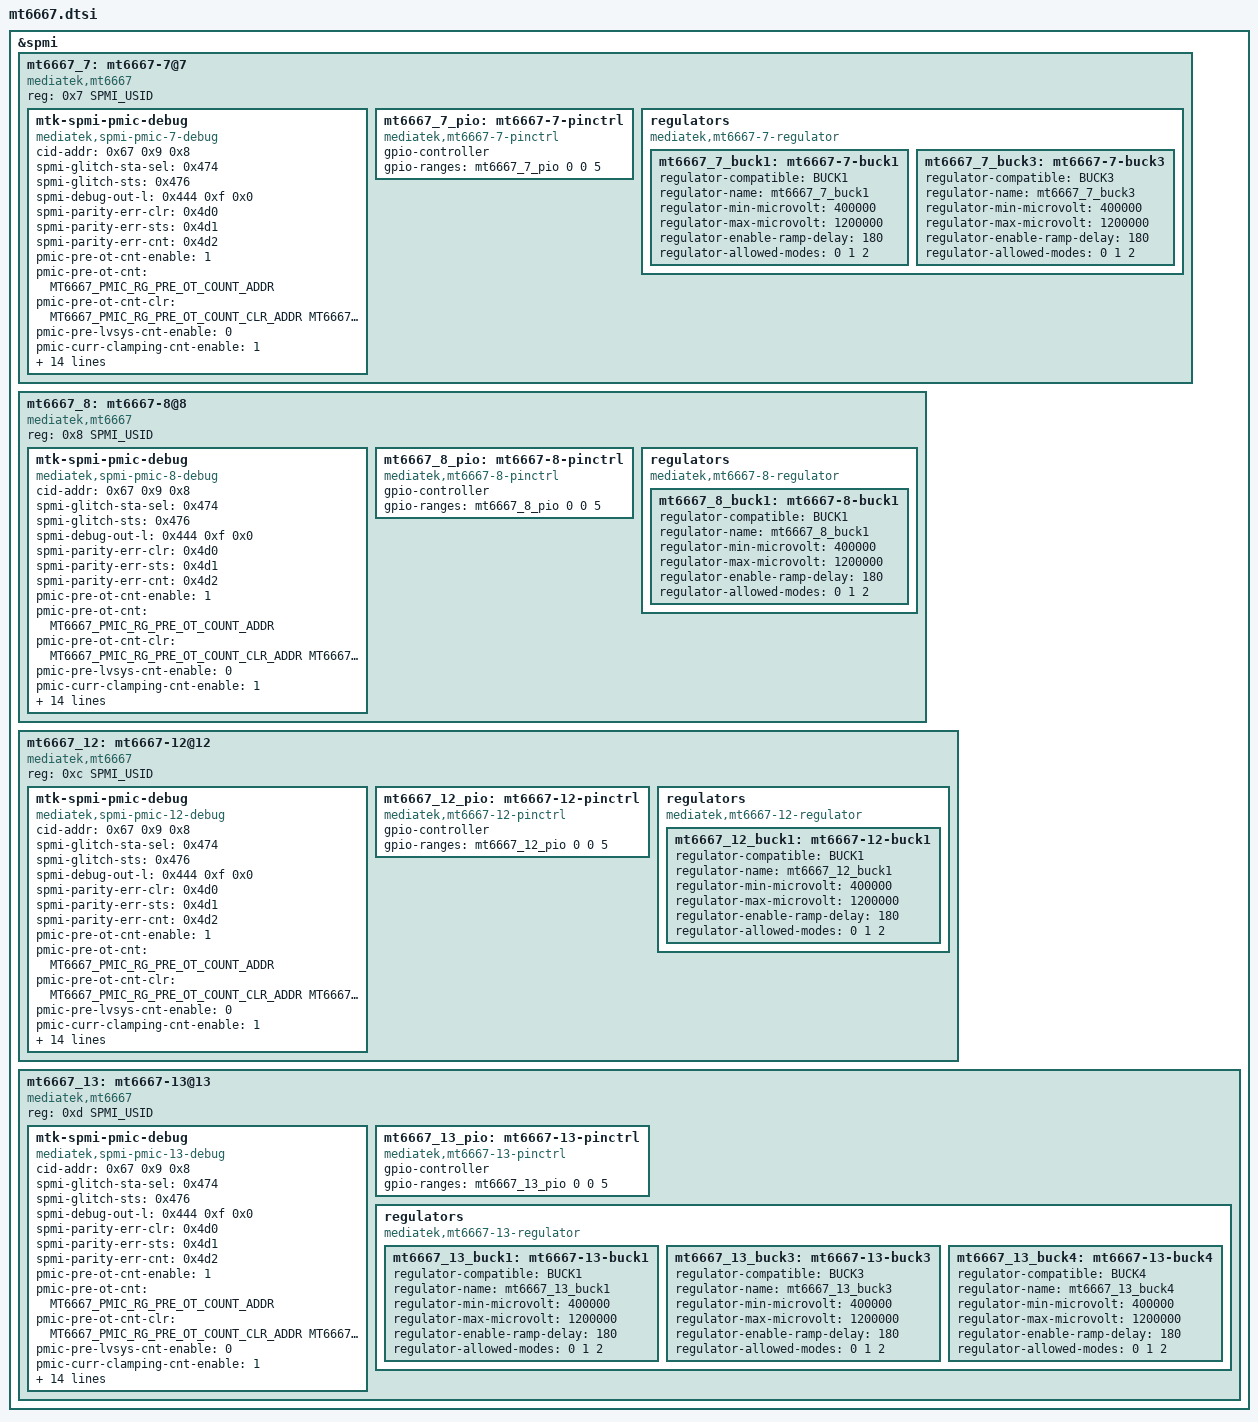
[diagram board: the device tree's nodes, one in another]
// SPDX-License-Identifier: GPL-2.0
/*
 * Copyright (c) 2024 MediaTek Inc.
 */
#include <dt-bindings/iio/mt635x-auxadc.h>
#include <dt-bindings/spmi/spmi.h>
#include <linux/mfd/mt6667/registers.h>

&spmi {
	#address-cells = <2>;
	#size-cells = <0>;
	mt6667_7: mt6667-7@7 {
		compatible = "mediatek,mt6667";
		reg = <0x7 SPMI_USID>;

		mtk-spmi-pmic-debug {
			compatible = "mediatek,spmi-pmic-7-debug";
			cid-addr = <0x67 0x9 0x8>;
			spmi-glitch-sta-sel = <0x474>;
			spmi-glitch-sts = <0x476>;
			spmi-debug-out-l = <0x444 0xf 0x0>;
			spmi-parity-err-clr = <0x4d0>;
			spmi-parity-err-sts = <0x4d1>;
			spmi-parity-err-cnt = <0x4d2>;
			pmic-pre-ot-cnt-enable = <1>;
			pmic-pre-ot-cnt = <MT6667_PMIC_RG_PRE_OT_COUNT_ADDR>;
			pmic-pre-ot-cnt-clr = <MT6667_PMIC_RG_PRE_OT_COUNT_CLR_ADDR
					       MT6667_PMIC_RG_PRE_OT_COUNT_CLR_MASK
					       MT6667_PMIC_RG_PRE_OT_COUNT_CLR_SHIFT>;
			pmic-pre-lvsys-cnt-enable = <0>;
			pmic-curr-clamping-cnt-enable = <1>;
			pmic-curr-clamping-cnt = <MT6667_PMIC_RG_BUCK1_OC_STS_CNT_ADDR
						  MT6667_PMIC_RG_BUCK2_OC_STS_CNT_ADDR
						  MT6667_PMIC_RG_BUCK3_OC_STS_CNT_ADDR
						  MT6667_PMIC_RG_BUCK4_OC_STS_CNT_ADDR>;
			pmic-curr-clamping-cnt-clr = <MT6667_PMIC_RG_BUCK_OC_STS_CNT_CLR_ADDR
						      MT6667_PMIC_RG_BUCK_OC_STS_CNT_CLR_MASK
						      MT6667_PMIC_RG_BUCK_OC_STS_CNT_CLR_SHIFT>;
			spmi-pmic-debug-rg-enable = <1>;
			spmi-pmic-debug-rg-addr = <MT6667_RG_SMT_SPMI_M_SCL_ADDR
						   MT6667_RG_SMT_SPMI_M_SDA_ADDR
						   MT6667_RG_OCTL_SPMI_M_SDA_ADDR
						   MT6667_GPIO_PULLEN0_4_ADDR
						   MT6667_GPIO_PULLEN0_5_ADDR
						   MT6667_RG_TOP_CFG_RSV1_0_ADDR
						   MT6667_RG_TOP_CFG_RSV1_1_ADDR
						   MT6667_GPIO_PULLSEL0_4_ADDR
						   MT6667_GPIO_PULLSEL0_5_ADDR>;
			spmi-pmic-debug-rg-mask = <MT6667_RG_SMT_SPMI_M_SCL_MASK
						   MT6667_RG_SMT_SPMI_M_SDA_MASK
						   MT6667_RG_OCTL_SPMI_M_SDA_MASK
						   MT6667_GPIO_PULLEN0_4_MASK
						   MT6667_GPIO_PULLEN0_5_MASK
						   MT6667_RG_TOP_CFG_RSV1_0_MASK
						   MT6667_RG_TOP_CFG_RSV1_1_MASK
						   MT6667_GPIO_PULLSEL0_4_MASK
						   MT6667_GPIO_PULLSEL0_5_MASK>;
			spmi-pmic-debug-rg-shift = <MT6667_RG_SMT_SPMI_M_SCL_SHIFT
						    MT6667_RG_SMT_SPMI_M_SDA_SHIFT
						    MT6667_RG_OCTL_SPMI_M_SDA_SHIFT
						    MT6667_GPIO_PULLEN0_4_SHIFT
						    MT6667_GPIO_PULLEN0_5_SHIFT
						    MT6667_RG_TOP_CFG_RSV1_0_SHIFT
						    MT6667_RG_TOP_CFG_RSV1_1_SHIFT
						    MT6667_GPIO_PULLSEL0_4_SHIFT
						    MT6667_GPIO_PULLSEL0_5_SHIFT>;
			rgs-npkt-cclp-err = <MT6667_RGS_NPKT_CCLP_ERR>;
			rgs-npkt-cclp-clr = <MT6667_RGS_NPKT_CCLP_CLR>;
			rgs-npkt-cclp-clr-enable = <1>;
		};

		mt6667_7_pio: mt6667-7-pinctrl {
			compatible = "mediatek,mt6667-7-pinctrl";
			gpio-controller;
			#gpio-cells = <2>;
			gpio-ranges = <&mt6667_7_pio 0 0 5>;
		};

		regulators {
			compatible = "mediatek,mt6667-7-regulator";
			mt6667_7_buck1: mt6667-7-buck1 {
				regulator-compatible = "BUCK1";
				regulator-name = "mt6667_7_buck1";
				regulator-min-microvolt = <400000>;
				regulator-max-microvolt = <1200000>;
				regulator-enable-ramp-delay = <180>;
				regulator-allowed-modes = <0 1 2>;
			};
			mt6667_7_buck3: mt6667-7-buck3 {
				regulator-compatible = "BUCK3";
				regulator-name = "mt6667_7_buck3";
				regulator-min-microvolt = <400000>;
				regulator-max-microvolt = <1200000>;
				regulator-enable-ramp-delay = <180>;
				regulator-allowed-modes = <0 1 2>;
				// regulator-always-on; // MM TODO:
			};
		};
	};

	mt6667_8: mt6667-8@8 {
		compatible = "mediatek,mt6667";
		reg = <0x8 SPMI_USID>;

		mtk-spmi-pmic-debug {
			compatible = "mediatek,spmi-pmic-8-debug";
			cid-addr = <0x67 0x9 0x8>;
			spmi-glitch-sta-sel = <0x474>;
			spmi-glitch-sts = <0x476>;
			spmi-debug-out-l = <0x444 0xf 0x0>;
			spmi-parity-err-clr = <0x4d0>;
			spmi-parity-err-sts = <0x4d1>;
			spmi-parity-err-cnt = <0x4d2>;
			pmic-pre-ot-cnt-enable = <1>;
			pmic-pre-ot-cnt = <MT6667_PMIC_RG_PRE_OT_COUNT_ADDR>;
			pmic-pre-ot-cnt-clr = <MT6667_PMIC_RG_PRE_OT_COUNT_CLR_ADDR
					       MT6667_PMIC_RG_PRE_OT_COUNT_CLR_MASK
					       MT6667_PMIC_RG_PRE_OT_COUNT_CLR_SHIFT>;
			pmic-pre-lvsys-cnt-enable = <0>;
			pmic-curr-clamping-cnt-enable = <1>;
			pmic-curr-clamping-cnt = <MT6667_PMIC_RG_BUCK1_OC_STS_CNT_ADDR
						  MT6667_PMIC_RG_BUCK2_OC_STS_CNT_ADDR
						  MT6667_PMIC_RG_BUCK3_OC_STS_CNT_ADDR
						  MT6667_PMIC_RG_BUCK4_OC_STS_CNT_ADDR>;
			pmic-curr-clamping-cnt-clr = <MT6667_PMIC_RG_BUCK_OC_STS_CNT_CLR_ADDR
						      MT6667_PMIC_RG_BUCK_OC_STS_CNT_CLR_MASK
						      MT6667_PMIC_RG_BUCK_OC_STS_CNT_CLR_SHIFT>;
			spmi-pmic-debug-rg-enable = <1>;
			spmi-pmic-debug-rg-addr = <MT6667_RG_SMT_SPMI_M_SCL_ADDR
						   MT6667_RG_SMT_SPMI_M_SDA_ADDR
						   MT6667_RG_OCTL_SPMI_M_SDA_ADDR
						   MT6667_GPIO_PULLEN0_4_ADDR
						   MT6667_GPIO_PULLEN0_5_ADDR
						   MT6667_RG_TOP_CFG_RSV1_0_ADDR
						   MT6667_RG_TOP_CFG_RSV1_1_ADDR
						   MT6667_GPIO_PULLSEL0_4_ADDR
						   MT6667_GPIO_PULLSEL0_5_ADDR>;
			spmi-pmic-debug-rg-mask = <MT6667_RG_SMT_SPMI_M_SCL_MASK
						   MT6667_RG_SMT_SPMI_M_SDA_MASK
						   MT6667_RG_OCTL_SPMI_M_SDA_MASK
						   MT6667_GPIO_PULLEN0_4_MASK
						   MT6667_GPIO_PULLEN0_5_MASK
						   MT6667_RG_TOP_CFG_RSV1_0_MASK
						   MT6667_RG_TOP_CFG_RSV1_1_MASK
						   MT6667_GPIO_PULLSEL0_4_MASK
						   MT6667_GPIO_PULLSEL0_5_MASK>;
			spmi-pmic-debug-rg-shift = <MT6667_RG_SMT_SPMI_M_SCL_SHIFT
						    MT6667_RG_SMT_SPMI_M_SDA_SHIFT
						    MT6667_RG_OCTL_SPMI_M_SDA_SHIFT
						    MT6667_GPIO_PULLEN0_4_SHIFT
						    MT6667_GPIO_PULLEN0_5_SHIFT
						    MT6667_RG_TOP_CFG_RSV1_0_SHIFT
						    MT6667_RG_TOP_CFG_RSV1_1_SHIFT
						    MT6667_GPIO_PULLSEL0_4_SHIFT
						    MT6667_GPIO_PULLSEL0_5_SHIFT>;
			rgs-npkt-cclp-err = <MT6667_RGS_NPKT_CCLP_ERR>;
			rgs-npkt-cclp-clr = <MT6667_RGS_NPKT_CCLP_CLR>;
			rgs-npkt-cclp-clr-enable = <1>;
		};

		mt6667_8_pio: mt6667-8-pinctrl {
			compatible = "mediatek,mt6667-8-pinctrl";
			gpio-controller;
			#gpio-cells = <2>;
			gpio-ranges = <&mt6667_8_pio 0 0 5>;
		};

		regulators {
			compatible = "mediatek,mt6667-8-regulator";
			mt6667_8_buck1: mt6667-8-buck1 {
				regulator-compatible = "BUCK1";
				regulator-name = "mt6667_8_buck1";
				regulator-min-microvolt = <400000>;
				regulator-max-microvolt = <1200000>;
				regulator-enable-ramp-delay = <180>;
				regulator-allowed-modes = <0 1 2>;
			};
		};
	};

	mt6667_12: mt6667-12@12 {
		compatible = "mediatek,mt6667";
		reg = <0xc SPMI_USID>;

		mtk-spmi-pmic-debug {
			compatible = "mediatek,spmi-pmic-12-debug";
			cid-addr = <0x67 0x9 0x8>;
			spmi-glitch-sta-sel = <0x474>;
			spmi-glitch-sts = <0x476>;
			spmi-debug-out-l = <0x444 0xf 0x0>;
			spmi-parity-err-clr = <0x4d0>;
			spmi-parity-err-sts = <0x4d1>;
			spmi-parity-err-cnt = <0x4d2>;
			pmic-pre-ot-cnt-enable = <1>;
			pmic-pre-ot-cnt = <MT6667_PMIC_RG_PRE_OT_COUNT_ADDR>;
			pmic-pre-ot-cnt-clr = <MT6667_PMIC_RG_PRE_OT_COUNT_CLR_ADDR
					       MT6667_PMIC_RG_PRE_OT_COUNT_CLR_MASK
					       MT6667_PMIC_RG_PRE_OT_COUNT_CLR_SHIFT>;
			pmic-pre-lvsys-cnt-enable = <0>;
			pmic-curr-clamping-cnt-enable = <1>;
			pmic-curr-clamping-cnt = <MT6667_PMIC_RG_BUCK1_OC_STS_CNT_ADDR
						  MT6667_PMIC_RG_BUCK2_OC_STS_CNT_ADDR
						  MT6667_PMIC_RG_BUCK3_OC_STS_CNT_ADDR
						  MT6667_PMIC_RG_BUCK4_OC_STS_CNT_ADDR>;
			pmic-curr-clamping-cnt-clr = <MT6667_PMIC_RG_BUCK_OC_STS_CNT_CLR_ADDR
						      MT6667_PMIC_RG_BUCK_OC_STS_CNT_CLR_MASK
						      MT6667_PMIC_RG_BUCK_OC_STS_CNT_CLR_SHIFT>;
			spmi-pmic-debug-rg-enable = <1>;
			spmi-pmic-debug-rg-addr = <MT6667_RG_SMT_SPMI_M_SCL_ADDR
						   MT6667_RG_SMT_SPMI_M_SDA_ADDR
						   MT6667_RG_OCTL_SPMI_M_SDA_ADDR
						   MT6667_GPIO_PULLEN0_4_ADDR
						   MT6667_GPIO_PULLEN0_5_ADDR
						   MT6667_RG_TOP_CFG_RSV1_0_ADDR
						   MT6667_RG_TOP_CFG_RSV1_1_ADDR
						   MT6667_GPIO_PULLSEL0_4_ADDR
						   MT6667_GPIO_PULLSEL0_5_ADDR>;
			spmi-pmic-debug-rg-mask = <MT6667_RG_SMT_SPMI_M_SCL_MASK
						   MT6667_RG_SMT_SPMI_M_SDA_MASK
						   MT6667_RG_OCTL_SPMI_M_SDA_MASK
						   MT6667_GPIO_PULLEN0_4_MASK
						   MT6667_GPIO_PULLEN0_5_MASK
						   MT6667_RG_TOP_CFG_RSV1_0_MASK
						   MT6667_RG_TOP_CFG_RSV1_1_MASK
						   MT6667_GPIO_PULLSEL0_4_MASK
						   MT6667_GPIO_PULLSEL0_5_MASK>;
			spmi-pmic-debug-rg-shift = <MT6667_RG_SMT_SPMI_M_SCL_SHIFT
						    MT6667_RG_SMT_SPMI_M_SDA_SHIFT
						    MT6667_RG_OCTL_SPMI_M_SDA_SHIFT
						    MT6667_GPIO_PULLEN0_4_SHIFT
						    MT6667_GPIO_PULLEN0_5_SHIFT
						    MT6667_RG_TOP_CFG_RSV1_0_SHIFT
						    MT6667_RG_TOP_CFG_RSV1_1_SHIFT
						    MT6667_GPIO_PULLSEL0_4_SHIFT
						    MT6667_GPIO_PULLSEL0_5_SHIFT>;
			rgs-npkt-cclp-err = <MT6667_RGS_NPKT_CCLP_ERR>;
			rgs-npkt-cclp-clr = <MT6667_RGS_NPKT_CCLP_CLR>;
			rgs-npkt-cclp-clr-enable = <1>;
		};

		mt6667_12_pio: mt6667-12-pinctrl {
			compatible = "mediatek,mt6667-12-pinctrl";
			gpio-controller;
			#gpio-cells = <2>;
			gpio-ranges = <&mt6667_12_pio 0 0 5>;
		};

		regulators {
			compatible = "mediatek,mt6667-12-regulator";
			mt6667_12_buck1: mt6667-12-buck1 {
				regulator-compatible = "BUCK1";
				regulator-name = "mt6667_12_buck1";
				regulator-min-microvolt = <400000>;
				regulator-max-microvolt = <1200000>;
				regulator-enable-ramp-delay = <180>;
				regulator-allowed-modes = <0 1 2>;
			};
		};
	};

	mt6667_13: mt6667-13@13 {
		compatible = "mediatek,mt6667";
		reg = <0xd SPMI_USID>;

		mtk-spmi-pmic-debug {
			compatible = "mediatek,spmi-pmic-13-debug";
			cid-addr = <0x67 0x9 0x8>;
			spmi-glitch-sta-sel = <0x474>;
			spmi-glitch-sts = <0x476>;
			spmi-debug-out-l = <0x444 0xf 0x0>;
			spmi-parity-err-clr = <0x4d0>;
			spmi-parity-err-sts = <0x4d1>;
			spmi-parity-err-cnt = <0x4d2>;
			pmic-pre-ot-cnt-enable = <1>;
			pmic-pre-ot-cnt = <MT6667_PMIC_RG_PRE_OT_COUNT_ADDR>;
			pmic-pre-ot-cnt-clr = <MT6667_PMIC_RG_PRE_OT_COUNT_CLR_ADDR
					       MT6667_PMIC_RG_PRE_OT_COUNT_CLR_MASK
					       MT6667_PMIC_RG_PRE_OT_COUNT_CLR_SHIFT>;
			pmic-pre-lvsys-cnt-enable = <0>;
			pmic-curr-clamping-cnt-enable = <1>;
			pmic-curr-clamping-cnt = <MT6667_PMIC_RG_BUCK1_OC_STS_CNT_ADDR
						  MT6667_PMIC_RG_BUCK2_OC_STS_CNT_ADDR
						  MT6667_PMIC_RG_BUCK3_OC_STS_CNT_ADDR
						  MT6667_PMIC_RG_BUCK4_OC_STS_CNT_ADDR>;
			pmic-curr-clamping-cnt-clr = <MT6667_PMIC_RG_BUCK_OC_STS_CNT_CLR_ADDR
						      MT6667_PMIC_RG_BUCK_OC_STS_CNT_CLR_MASK
						      MT6667_PMIC_RG_BUCK_OC_STS_CNT_CLR_SHIFT>;
			spmi-pmic-debug-rg-enable = <1>;
			spmi-pmic-debug-rg-addr = <MT6667_RG_SMT_SPMI_M_SCL_ADDR
						   MT6667_RG_SMT_SPMI_M_SDA_ADDR
						   MT6667_RG_OCTL_SPMI_M_SDA_ADDR
						   MT6667_GPIO_PULLEN0_4_ADDR
						   MT6667_GPIO_PULLEN0_5_ADDR
						   MT6667_RG_TOP_CFG_RSV1_0_ADDR
						   MT6667_RG_TOP_CFG_RSV1_1_ADDR
						   MT6667_GPIO_PULLSEL0_4_ADDR
						   MT6667_GPIO_PULLSEL0_5_ADDR>;
			spmi-pmic-debug-rg-mask = <MT6667_RG_SMT_SPMI_M_SCL_MASK
						   MT6667_RG_SMT_SPMI_M_SDA_MASK
						   MT6667_RG_OCTL_SPMI_M_SDA_MASK
						   MT6667_GPIO_PULLEN0_4_MASK
						   MT6667_GPIO_PULLEN0_5_MASK
						   MT6667_RG_TOP_CFG_RSV1_0_MASK
						   MT6667_RG_TOP_CFG_RSV1_1_MASK
						   MT6667_GPIO_PULLSEL0_4_MASK
						   MT6667_GPIO_PULLSEL0_5_MASK>;
			spmi-pmic-debug-rg-shift = <MT6667_RG_SMT_SPMI_M_SCL_SHIFT
						    MT6667_RG_SMT_SPMI_M_SDA_SHIFT
						    MT6667_RG_OCTL_SPMI_M_SDA_SHIFT
						    MT6667_GPIO_PULLEN0_4_SHIFT
						    MT6667_GPIO_PULLEN0_5_SHIFT
						    MT6667_RG_TOP_CFG_RSV1_0_SHIFT
						    MT6667_RG_TOP_CFG_RSV1_1_SHIFT
						    MT6667_GPIO_PULLSEL0_4_SHIFT
						    MT6667_GPIO_PULLSEL0_5_SHIFT>;
			rgs-npkt-cclp-err = <MT6667_RGS_NPKT_CCLP_ERR>;
			rgs-npkt-cclp-clr = <MT6667_RGS_NPKT_CCLP_CLR>;
			rgs-npkt-cclp-clr-enable = <1>;
		};

		mt6667_13_pio: mt6667-13-pinctrl {
			compatible = "mediatek,mt6667-13-pinctrl";
			gpio-controller;
			#gpio-cells = <2>;
			gpio-ranges = <&mt6667_13_pio 0 0 5>;
		};

		regulators {
			compatible = "mediatek,mt6667-13-regulator";
			mt6667_13_buck1: mt6667-13-buck1 {
				regulator-compatible = "BUCK1";
				regulator-name = "mt6667_13_buck1";
				regulator-min-microvolt = <400000>;
				regulator-max-microvolt = <1200000>;
				regulator-enable-ramp-delay = <180>;
				regulator-allowed-modes = <0 1 2>;
			};
			mt6667_13_buck3: mt6667-13-buck3 {
				regulator-compatible = "BUCK3";
				regulator-name = "mt6667_13_buck3";
				regulator-min-microvolt = <400000>;
				regulator-max-microvolt = <1200000>;
				regulator-enable-ramp-delay = <180>;
				regulator-allowed-modes = <0 1 2>;
				// regulator-always-on;
			};
			mt6667_13_buck4: mt6667-13-buck4 {
				regulator-compatible = "BUCK4";
				regulator-name = "mt6667_13_buck4";
				regulator-min-microvolt = <400000>;
				regulator-max-microvolt = <1200000>;
				regulator-enable-ramp-delay = <180>;
				regulator-allowed-modes = <0 1 2>;
			};
		};
	};
};
